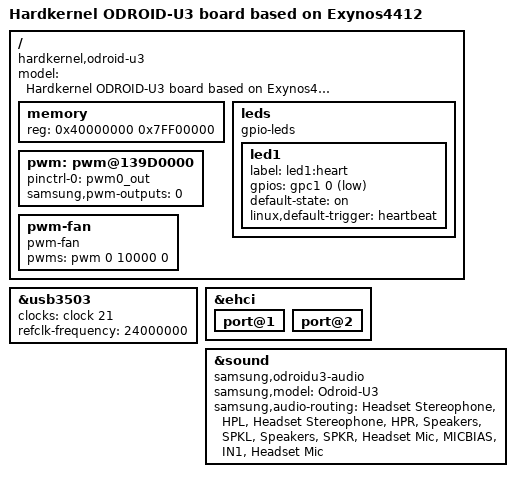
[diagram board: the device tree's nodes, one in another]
/*
 * Hardkernel's Exynos4412 based ODROID-U3 board device tree source
 *
 * Copyright (c) 2014 Marek Szyprowski <m.szyprowski@samsung.com>
 *
 * Device tree source file for Hardkernel's ODROID-U3 board which is based
 * on Samsung's Exynos4412 SoC.
 *
 * This program is free software; you can redistribute it and/or modify
 * it under the terms of the GNU General Public License version 2 as
 * published by the Free Software Foundation.
*/

/dts-v1/;
#include "exynos4412-odroid-common.dtsi"

/ {
	model = "Hardkernel ODROID-U3 board based on Exynos4412";
	compatible = "hardkernel,odroid-u3", "samsung,exynos4412", "samsung,exynos4";

	memory {
		reg = <0x40000000 0x7FF00000>;
	};

	leds {
		compatible = "gpio-leds";
		led1 {
			label = "led1:heart";
			gpios = <&gpc1 0 1>;
			default-state = "on";
			linux,default-trigger = "heartbeat";
		};
	};

	pwm: pwm@139D0000 {
		pinctrl-0 = <&pwm0_out>;
		pinctrl-names = "default";
		samsung,pwm-outputs = <0>;
		status = "okay";
	};

	pwm-fan {
		compatible = "pwm-fan";
		status = "okay";
		pwms = <&pwm 0 10000 0>;
	};
};

&usb3503 {
	clock-names = "refclk";
	clocks = <&clock 21>;
	refclk-frequency = <24000000>;
};

&ehci {
	port@1 {
		status = "okay";
	};
	port@2 {
		status = "okay";
	};
};

&sound {
	compatible = "samsung,odroidu3-audio";
	samsung,model = "Odroid-U3";
	samsung,audio-routing =
		"Headset Stereophone", "HPL",
		"Headset Stereophone", "HPR",
		"Speakers", "SPKL",
		"Speakers", "SPKR",
		"Headset Mic", "MICBIAS",
		"IN1", "Headset Mic";
};
